# V3s register map
Vendor: Allwinner; Series: V3s; File version: 0.1
CPU: ARM Cortex-A7 MP1 0, little endian, MPU, no FPU, 0 interrupt priority bits
Registers are 32-bit, read-write, reset 0x0 unless marked. A register's access mark holds for its fields unless they carry their own. Offsets are from the block's base; [hi:lo] are bit positions; lines under a group give offsets from that group; {n}, {i} and the like mark numbered series.

## DMA
Base 0x01C02000
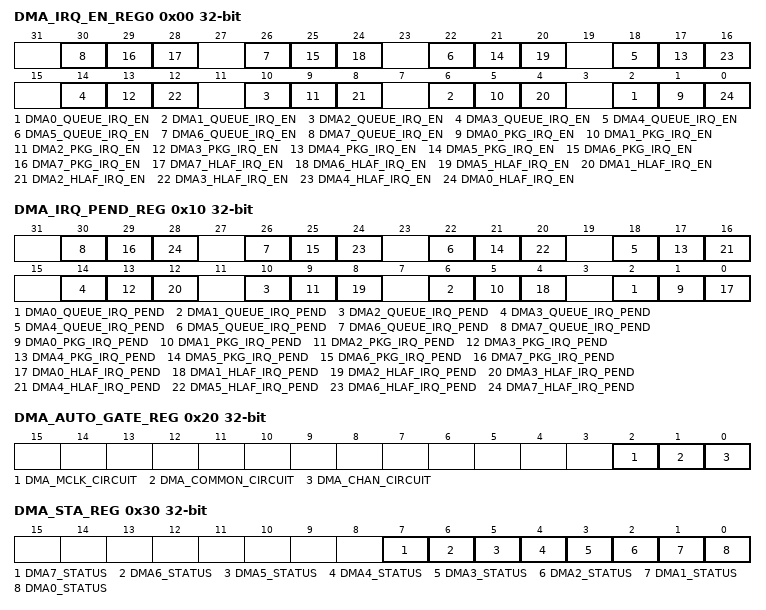
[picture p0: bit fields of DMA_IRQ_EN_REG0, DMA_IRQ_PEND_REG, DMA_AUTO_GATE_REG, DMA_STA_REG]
0x00 DMA_IRQ_EN_REG0
  [all] fields
    0=Disable, 1: Enable
  [4n+2] DMA{n}_QUEUE_IRQ_EN (n=0..7) — DMA {n} Queue End Transfer Interrupt Enable. 0: Disable, 1: Enable.
  [4n+1] DMA{n}_PKG_IRQ_EN (n=0..7) — DMA {n} Package End Transfer Interrupt Enable. 0: Disable, 1: Enable.
  [28] DMA7_HLAF_IRQ_EN — DMA 7 Half Package Transfer Interrupt Enable. 0: Disable, 1: Enable.
  [24] DMA6_HLAF_IRQ_EN — DMA 6 Half Package Transfer Interrupt Enable. 0: Disable, 1: Enable.
  [20] DMA5_HLAF_IRQ_EN — DMA 5 Half package Transfer Interrupt Enable. 0: Disable, 1: Enable.
  [4n] DMA{n}_HLAF_IRQ_EN (n=1..4) — DMA {n} Half Package Transfer Interrupt Enable. 0: Disable, 1: Enable.
  [0] DMA0_HLAF_IRQ_EN — DMA 0 Half Package Transfer Interrupt Enable. 0: Disable, 1: Enable
0x10 DMA_IRQ_PEND_REG — DMA IRQ Pending Register
  [all] fields
    0=No effect, 1: Pending
  [4n+2] DMA{n}_QUEUE_IRQ_PEND (n=0..7) — DMA {n} Queue End Transfer Interrupt Pending. Set 1 to the bit will clear it. 0: No effect, 1: Pending.
  [4n+1] DMA{n}_PKG_IRQ_PEND (n=0..7) — DMA {n} Package End Transfer Interrupt Pending. Set 1 to the bit will clear it. 0: No effect, 1: Pending.
  [4n] DMA{n}_HLAF_IRQ_PEND (n=0..7) — DMA {n} Half Package Transfer Interrupt Pending. Set 1 to the bit will clear it. 0: No effect, 1: Pending.
0x20 DMA_AUTO_GATE_REG — DMA Auto Gating Register
  [all] fields
    0=Auto_gating_enable; 1=Auto gating disable
  [2] DMA_MCLK_CIRCUIT — DMA MCLK interface circuit auto gating bit. 0: Auto gating enable 1: Auto gating disable.
  [1] DMA_COMMON_CIRCUIT — DMA common circuit auto gating bit. 0: Auto gating enable 1: Auto gating disable.
  [0] DMA_CHAN_CIRCUIT — DMA channel circuit auto gating bit. 0: Auto gating enable 1: Auto gating disable.
0x30 DMA_STA_REG — DMA Status Register
  [all] fields
    0=Idle; 1=Busy
  [7] DMA7_STATUS ro — DMA Channel 7 Status. 0: Idle 1: Busy
  [6] DMA6_STATUS ro — DMA Channel 6 Status. 0: Idle 1: Busy
  [5] DMA5_STATUS ro — DMA Channel 5 Status. 0: Idle 1: Busy
  [4] DMA4_STATUS ro — DMA Channel 4 Status. 0: Idle 1: Busy.
  [3] DMA3_STATUS ro — DMA Channel 3 Status. 0: Idle 1: Busy.
  [2] DMA2_STATUS ro — DMA Channel 2 Status. 0: Idle, 1: Busy.
  [1] DMA1_STATUS ro — DMA Channel 1 Status. 0: Idle, 1: Busy.
  [0] DMA0_STATUS ro — DMA Channel 0 Status. 0: Idle, 1: Busy.
{0x100+0x40*i} _N[{i}] (i=0..7) group
  0x00 DMA_EN_REG — DMA Channel Enable Register (N=0~7)
    [0] DMA_EN — DMA Channel Enable 0: Disable 1: Enable.
      0=Disable; 1=Enable
  0x04 DMA__PAU_REG
    [0] DMA_PAUSE — Pausing DMA Channel Transfer Data. 0: Resume Transferring, 1: Pause Transferring.
      0=Resume Transferring,; 1=Pause Transferring
  0x08 DMA_DESC_ADDR_REG — DMA Channel Start Address Register(N=0~7)
    [31:0] DMA_DESC_ADDR — DMA Channel Descriptor Address.
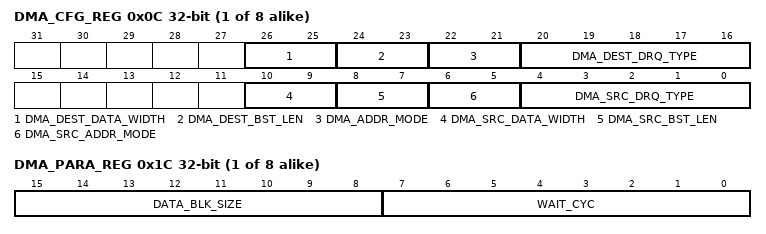
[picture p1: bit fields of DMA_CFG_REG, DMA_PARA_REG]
  0x0C DMA_CFG_REG — DMA Channel Configuration Register(N=0~7)
    [26:25] DMA_DEST_DATA_WIDTH ro — DMA Destination Data Width. 00: 8-bit 01: 16-bit 10: 32-bit 11: /
      0=_8_bit; 1=_16_bit; 2=_32_bit
    [24:23] DMA_DEST_BST_LEN ro — DMA Destination Burst Length. 00: 1 01: / 10: 8 11: /
      0=_1; 2=_8
    [22:21] DMA_ADDR_MODE ro — DMA Destination Address Mode 0x0: Linear Mode 0x1: IO Mode 0x2: / 0x3: /
      0=Linear Mode; 1=IO (IO Mode)
    [20:16] DMA_DEST_DRQ_TYPE ro — DMA Destination DRQ Type The details in DRQ Type and Port Corresponding Relation.
    [10:9] DMA_SRC_DATA_WIDTH ro — DMA Source Data Width. 00: 8-bit 01: 16-bit 10: 32-bit 11: /
      0=_8_bit; 1=_16_bit; 2=_32_bit
    [8:7] DMA_SRC_BST_LEN ro — DMA Source Burst Length. 00: 1 01: / 10: 8 11: /
      0=_1; 2=_8
    [6:5] DMA_SRC_ADDR_MODE ro — DMA Source Address Mode 0x0: Linear Mode 0x1: IO Mode 0x2: / 0x3: /
      0=Linear Mode; 1=IO (IO Mode)
    [4:0] DMA_SRC_DRQ_TYPE ro — DMA Source DRQ Type The details in DRQ Type and Port Corresponding Relation.
  0x10 DMA_CUR_SRC_REG — DMA Channel Current Source Register(N=0~7)
    [31:0] DMA_CUR_SRC ro — DMA Channel Current Source Address, read only.
  0x14 DMA_CUR_DEST_REG — DMA Channel Current Destination Register(N=0~7)
    [31:0] DMA_CUR_DEST ro — DMA Channel Current Destination Address, read only.
  0x1C DMA_PARA_REG — DMA Channel Parameter Register(N=0~7)
    [15:8] DATA_BLK_SIZE ro — Data Block Size N.
    [7:0] WAIT_CYC ro — Wait Clock Cycles n.
{0x118+0x40*i} DMA_BCNT_LEFT_REG[{i}] (i=0..11) — DMA Channel Byte Counter Left Register(N=0~7)
  [24:0] DMA_BCNT_LEFT ro — DMA Channel Byte Counter Left, read only.
